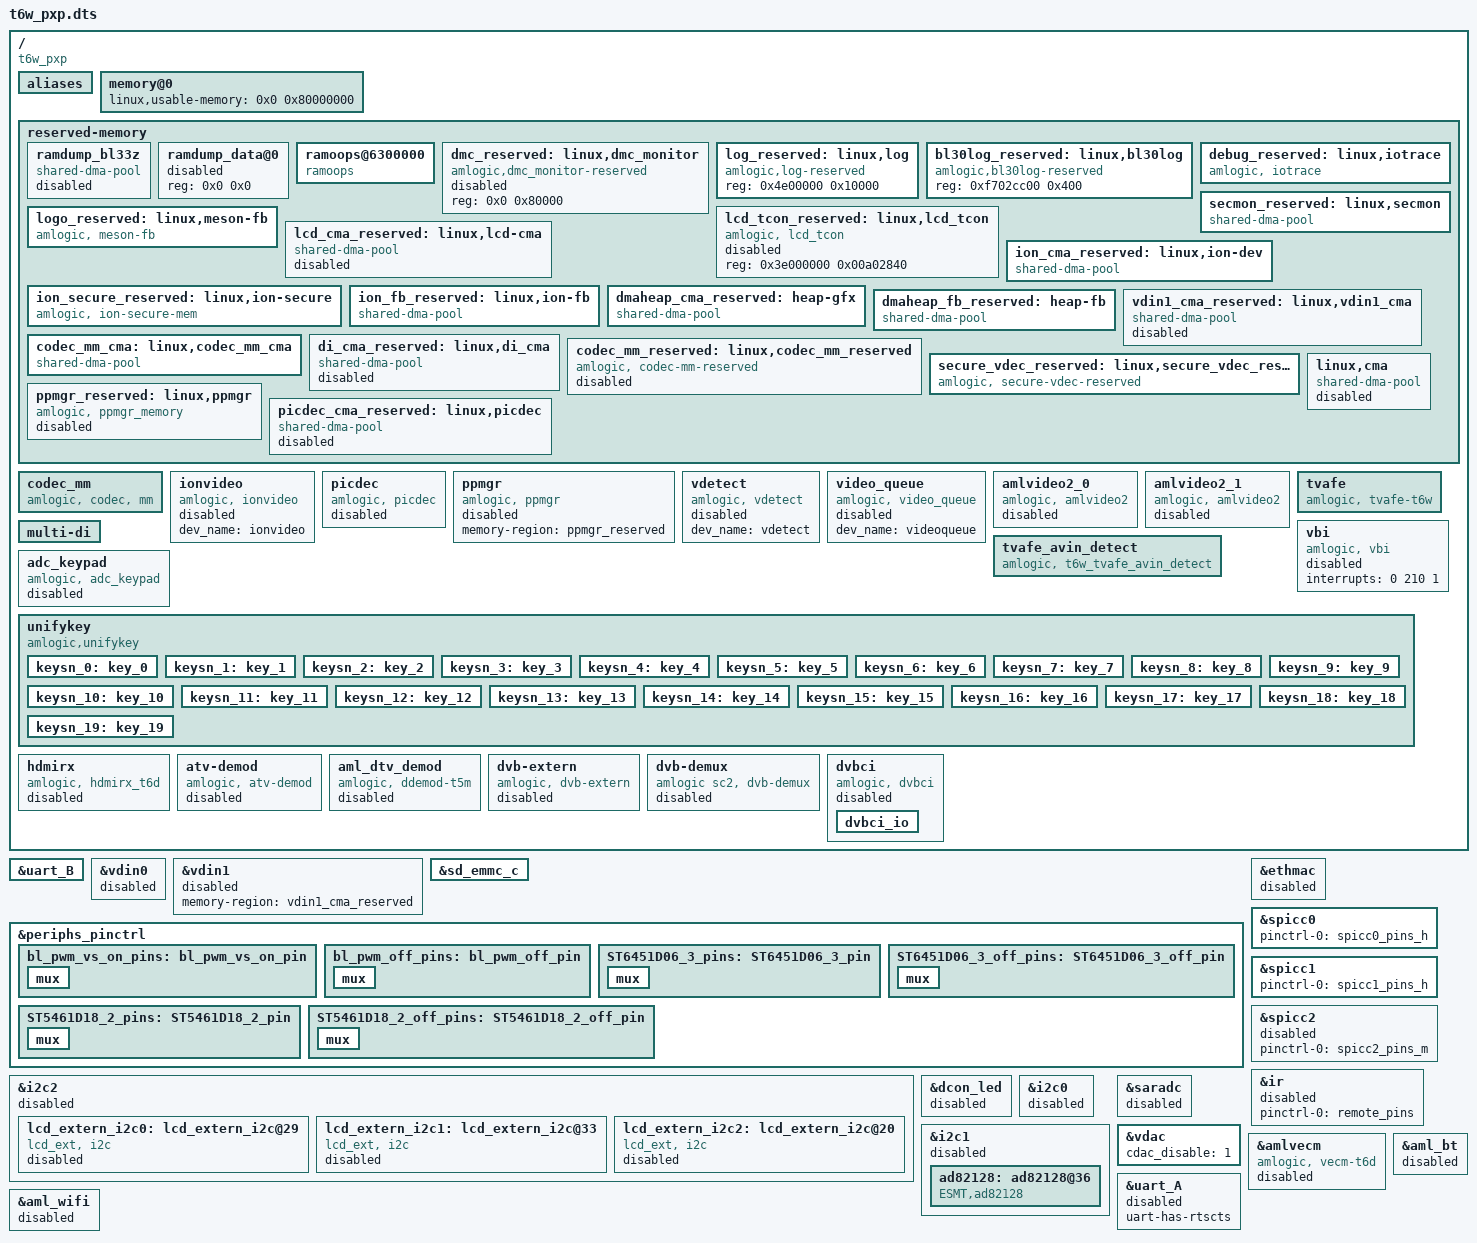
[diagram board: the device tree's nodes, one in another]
// SPDX-License-Identifier: (GPL-2.0+ OR MIT)
/*
 * Copyright (c) 2019 Amlogic, Inc. All rights reserved.
 */

/dts-v1/;

#include "mesont6w.dtsi"
#include "hdr10plus.dtsi"
//#include "mesont6d_drm.dtsi"
#include "firmware_ab.dtsi"
#include "mesont6w_pxp-panel.dtsi"
//#include "mesont6d_audio.dtsi"
/ {
	amlogic-dt-id = "t6w_pxp";
	compatible = "t6w_pxp";
	interrupt-parent = <&gic>;
	#address-cells = <1>;
	#size-cells = <1>;

	aliases {
		serial0 = &uart_B;
		serial1 = &uart_A;
		serial2 = &uart_C;
		tsensor0 = &cpu_tsensor;
		tsensor1 = &top_tsensor;
		spi0 = &spi_nfc;
		spi1 = &spicc0;
		spi2 = &spicc1;
		spi3 = &spicc2;
		spi4 = &spicc3;
		i2c0 = &i2c0;
		i2c1 = &i2c1;
		i2c2 = &i2c2;
		i2c3 = &i2c3;
	};

	memory@0 {
		device_type = "memory";
		linux,usable-memory = <0x0 0x80000000>;
	};

	reserved-memory {
		#address-cells = <1>;
		#size-cells = <1>;
		ranges;

		/* global autoconfigured region for contiguous allocations */
		ramdump_bl33z {
			compatible = "shared-dma-pool";
			size = <0x01800000>;
			alignment = <0x00400000>;
			alloc-ranges = <0x05000000 0x07000000>;
			linux,contiguous-region;
			no-map;
			status = "disabled";
		};

		ramdump_data@0 {
			reg = <0x0 0x0>;
			status = "disabled"; /* disabled as default */
		};

		ramoops@6300000 {
			compatible = "ramoops";
			reg = <0x06300000 0x00080000>;/* addr set in uboot */
			record-size = <0x30000>;
			console-size = <0x40000>;
			ftrace-size = <0x0>;
			pmsg-size = <0x10000>;
		};

		dmc_reserved:linux,dmc_monitor {
			compatible = "amlogic,dmc_monitor-reserved";
			reg = <0x0 0x80000>;
			status = "disabled";
		};

		log_reserved:linux,log {
			compatible = "amlogic,log-reserved";
			reg = <0x4e00000 0x10000>;
		};

		bl30log_reserved:linux,bl30log {
			compatible = "amlogic,bl30log-reserved";
			reg = <0xf702cc00 0x400>;
		};

		debug_reserved:linux,iotrace {
			compatible = "amlogic, iotrace";
			reg = <0x04f00000 0x00100000>;
			io-size = <0x19800>;
			sched-size = <0x2000>;
			irq-size = <0x1000>;
			smc-size = <0x1000>;
			misc-size = <0x1000>;
			iotm-size = <0x3a980>; //240k; v1:20000; v2:15000
		};

		secmon_reserved:linux,secmon {
			compatible = "shared-dma-pool";
			no-map;
			alignment = <0x00100000>;
			reg = <0x05000000 0x01300000>;
		};

		logo_reserved:linux,meson-fb {
			compatible = "amlogic, meson-fb";
			size = <0x800000>;
			alignment = <0x400000>;
			reg = <0x3f800000 0x800000>;
		};

		lcd_tcon_reserved:linux,lcd_tcon {
			compatible = "amlogic, lcd_tcon";
			reg = <0x3e000000 0x00a02840>;
			status = "disabled";
			//no-map;
		};

		lcd_cma_reserved:linux,lcd-cma {
			compatible = "shared-dma-pool";
			reusable;
			/* 512k for lcd dma data */
			size = <0x00080000>;
			reg = <0x3ea80000 0x00080000>;
			status = "disabled";
		};

		ion_cma_reserved:linux,ion-dev {
			compatible = "shared-dma-pool";
			reusable;
			size = <0x0>;
			alignment = <0x400000>;
		};
		/* secure ion for gpu, advice size is 80M */
		ion_secure_reserved:linux,ion-secure {
			compatible = "amlogic, ion-secure-mem";
			no-map;
			size = <0x0>;
			alignment = <0x400000>;
		};
		ion_fb_reserved:linux,ion-fb {
			compatible = "shared-dma-pool";
			reusable;
			size = <0x0>;
			alignment = <0x400000>;
		};
		dmaheap_cma_reserved:heap-gfx {
			compatible = "shared-dma-pool";
			reusable;
			/* 1080p TV android16 size 88M */
			size = <0x5800000>;
			alignment = <0x400000>;
			alloc-ranges = <0x00000000 0x1d400000>;
		};
		dmaheap_fb_reserved:heap-fb {
			compatible = "shared-dma-pool";
			reusable;
			/* 1080p TV android16 size 28M */
			size = <0x1c00000>;
			alignment = <0x400000>;
			alloc-ranges = <0x00000000 0x1d400000>;
		};

		/*  vdin0 CMA pool */
		/*vdin0_cma_reserved:linux,vdin0_cma {*/
		/*	compatible = "shared-dma-pool";*/
		/*	reusable;*/
			/* up to 1920x1080 yuv422 8bit and 5 buffers
			 * 1920x1080x2x5 = 20 M
			 */
		/*	size = <0x0 0x01400000>;*/
		/*	alignment = <0x0 0x400000>;*/
		/*};*/
		/*  vdin1 CMA pool */
		vdin1_cma_reserved:linux,vdin1_cma {
			compatible = "shared-dma-pool";
			reusable;
			/* up to 1920x1080 yuv422 8bit and 5 buffers
			 * 1920x1080x2x5 = 20 M
			 */
			size = <0x01400000>;
			alignment = <0x400000>;
			alloc-ranges = <0x00000000 0x1d400000>;
			status = "disabled";
		};

		codec_mm_cma:linux,codec_mm_cma {
			compatible = "shared-dma-pool";
			reusable;
			/* ion_codec_mm max can alloc size 80M*/
			size = <0xD000000>;
			alignment = <0x400000>;
			alloc-ranges = <0x30000000 0x10000000>;
			linux,contiguous-region;
		};

		/*di CMA pool */
		di_cma_reserved:linux,di_cma {
			compatible = "shared-dma-pool";
			reusable;
			/* buffer_size = 3621952(yuv422 8bit)
			 *  | 4736064(yuv422 10bit)
			 *  | 4074560(yuv422 10bit full pack mode)
			 * 10x3621952=34.6M(0x23) support 8bit
			 * 10x4736064=45.2M(0x2e) support 12bit
			 * 10x4074560=40M(0x28) support 10bit
			 */
			size = <0x000000>;
			//size = <0x0 0x0>;
			alignment = <0x400000>;
			alloc-ranges = <0x0 0x1d400000>;
			status = "disabled";
		};
		/* codec shared reserved */
		codec_mm_reserved:linux,codec_mm_reserved {
			compatible = "amlogic, codec-mm-reserved";
			size = <0x100000>;
			alignment = <0x100000>;
			//no-map;
			status = "disabled";
		};

		secure_vdec_reserved:linux,secure_vdec_reserved {
			compatible = "amlogic, secure-vdec-reserved";
			no-map;
			size = <0x400000>;
			alignment = <0x100000>;
		};

		/* POST PROCESS MANAGER */
		ppmgr_reserved:linux,ppmgr {
			compatible = "amlogic, ppmgr_memory";
			size = <0x100000>;
			alignment = <0x100000>;
			linux,contiguous-region;
			status = "disabled";
		};

		picdec_cma_reserved:linux,picdec {
			compatible = "shared-dma-pool";
			reusable;
			size = <0x100000>;
			alignment = <0x100000>;
			linux,contiguous-region;
			status = "disabled";
		};

		/* global autoconfigured region for contiguous allocations */
		linux,cma {
			compatible = "shared-dma-pool";
			reusable;
			size = <0x800000>;
			alignment = <0x400000>;
			alloc-ranges = <0x0 0x1d400000>;
			linux,cma-default;
			status = "disabled";
		};
	};

	codec_mm {
		compatible = "amlogic, codec, mm";
		memory-region = <&codec_mm_cma &codec_mm_reserved &secure_vdec_reserved>;
		dev_name = "codec_mm";
		status = "okay";
		/* secure memory controller para <switch  align_2n> */
		secure_ctrl_para = <1 16>;
	};

	ionvideo {
		compatible = "amlogic, ionvideo";
		dev_name = "ionvideo";
		status = "disabled";
	};

	picdec {
		compatible = "amlogic, picdec";
		memory-region = <&picdec_cma_reserved>;
		dev_name = "picdec";
		status = "disabled";
	};
	ppmgr {
		compatible = "amlogic, ppmgr";
		memory-region = <&ppmgr_reserved>;
		status = "disabled";
	};
	vdetect {
		compatible = "amlogic, vdetect";
		dev_name = "vdetect";
		status = "disabled";
	};

	video_queue {
		compatible = "amlogic, video_queue";
		dev_name = "videoqueue";
		status = "disabled";
	};
	amlvideo2_0 {
		compatible = "amlogic, amlvideo2";
		dev_name = "amlvideo2";
		status = "disabled";
		amlvideo2_id = <0>;
		cma_mode = <1>;
	};

	amlvideo2_1 {
		compatible = "amlogic, amlvideo2";
		dev_name = "amlvideo2";
		status = "disabled";
		amlvideo2_id = <1>;
		cma_mode = <1>;
	};

	tvafe_avin_detect {
		compatible = "amlogic, t6w_tvafe_avin_detect";
		status = "okay";
		device_mask = <1>;/*bit0:ch1;bit1:ch2*/
		reg = <0xfe00a000 0x400>; /* cvbs irq base */
		interrupts = <0 173 1>;
	};

	tvafe {
		compatible = "amlogic, tvafe-t6w";
		/*memory-region = <&tvafe_cma_reserved>;*/
		status = "okay";
		flag_cma = <1>;/*1:share with codec_mm;0:cma alone*/
		cma_size = <5>;/*MByte*/
		reg = <0xfe072000 0x2000/*tvafe reg base*/
			0xfe008000 0x2000>; /*ana reg base*/
		reserve-iomap = "true";
		tvafe_id = <0>;
		//pinctrl-names = "default";
		/*!!particular sequence, no more and no less!!!*/
		tvafe_pin_mux = <
				3 /* TVAFE_CVBS_IN2, CVBS_IN0 = 0 */
				1 /* TVAFE_CVBS_IN0, CVBS_IN1 */
				2 /* TVAFE_CVBS_IN1, CVBS_IN2 */
				4 /* TVAFE_CVBS_IN3, CVBS_IN3 */
		>;
		clocks = <&clkc CLKID_CDAC_CLK>;
		clock-names = "vdac_clk_gate";
		cutwindow_val_h = <0 0 0 0 8>; /* level 0~4 */
		cutwindow_val_v = <4 8 14 16 24>;  /* level 0~4 */
		horizontal_dir0 = <148 148 148 148 148>;
		horizontal_dir1 = <148 168 166 160 148>;
		horizontal_stp0 = <0 0 0 0 0>;
		horizontal_stp1 = <0 0 0 0 0>;
		macrovision = <1>;
	};

	vbi {
		compatible = "amlogic, vbi";
		status = "disabled";
		interrupts = <0 210 1>;
	};

	multi-di {
		//status = "disabled";
		/***************************************************
		 * memory: default is 4
		 *	0:use reserved;
		 *	1:use cma;
		 *	2:use cma as reserved
		 *  4:use codec mem
		 ***************************************************/
		flag_cma = <4>;//
		//memory-region = <&di_cma_reserved>;
		/***************************************************
		 * clock-range: <min max>
		 *	default: <334 667>
		 ***************************************************/
		//clock-range = <334 667>;
		/***************************************************
		 * en_4k: t5w support 4k
		 ***************************************************/
		//en_4k = <1>;
		//keep_dec_vf = <2>;
		//po_fmt = <6>;
		/***************************************************
		 * post_nub: default is 11 (T7/T3/SC2/S4 new path)
		 * local 7*4075520 = 28
		 * post 11*5222400 = 56 //??
		 ***************************************************/
		post_nub = <11>;
		/***************************************************
		 * 0:not support
		 * bit 0: for 4k
		 * bit 1: for 1080p
		 ***************************************************/
		//alloc_sct = <1>;
		/***************************************************
		 * hf: default is 0 (T7/T3/SC2/S4 new path)
		 * 0:not enable;
		 * 1: enable
		 ***************************************************/
		hf = <0>;
		//afbce_loss_en = <1>;
		/***************************************************
		 * loss mode for di out (T5w)
		 * 0:not set loss mode for di out;
		 * 1:1:check the loss flag in vf and set for di
		 ***************************************************/
	};/* end of multi-di */

	/* for external keypad */
	adc_keypad {
		compatible = "amlogic, adc_keypad";
		status = "disabled";
		key_name = "power","vol-","vol+","enter","menu","source","exit";
		key_num = <7>;
		io-channels = <&saradc SARADC_CH1>,<&saradc SARADC_CH2>;
		io-channel-names = "key-chan-1", "key-chan-2";
		key_chan = <SARADC_CH1 SARADC_CH1 SARADC_CH1 SARADC_CH1
			SARADC_CH1 SARADC_CH2 SARADC_CH2>;
		key_code = <116 114 115 28 139 466 174>;
		key_val = <0 252 468 684 892 252 468>; // Unit: millivolt
		key_tolerance = <70 70 70 70 70 70 70>; // Unit: millivolt
		mboxes = <&mbox_fifo T6W_REE2AO_KEYPAD>;
	};

	unifykey {
		compatible = "amlogic,unifykey";

		unifykey-num = <20>;
		unifykey-index-0 = <&keysn_0>;
		unifykey-index-1 = <&keysn_1>;
		unifykey-index-2 = <&keysn_2>;
		unifykey-index-3 = <&keysn_3>;
		unifykey-index-4 = <&keysn_4>;
		unifykey-index-5 = <&keysn_5>;
		unifykey-index-6 = <&keysn_6>;
		unifykey-index-7 = <&keysn_7>;
		unifykey-index-8 = <&keysn_8>;
		unifykey-index-9 = <&keysn_9>;
		unifykey-index-10= <&keysn_10>;
		unifykey-index-11 = <&keysn_11>;
		unifykey-index-12 = <&keysn_12>;
		unifykey-index-13 = <&keysn_13>;
		unifykey-index-14 = <&keysn_14>;
		unifykey-index-15 = <&keysn_15>;
		unifykey-index-16 = <&keysn_16>;
		unifykey-index-17 = <&keysn_17>;
		unifykey-index-18 = <&keysn_18>;
		unifykey-index-19 = <&keysn_19>;

		keysn_0: key_0{
			key-name = "usid";
			key-device = "normal";
			key-permit = "read","write","del";
		};
		keysn_1:key_1{
			key-name = "mac";
			key-device  = "normal";
			key-permit = "read","write","del";
		};
		keysn_2:key_2{
			key-name = "hdcp";
			key-device = "secure";
			key-type  = "sha1";
			key-permit = "read","write","del";
		};
		keysn_3:key_3{
			key-name = "secure_boot_set";
			key-device = "efuse";
			key-permit = "write";
		};
		keysn_4:key_4{
			key-name = "mac_bt";
			key-device = "normal";
			key-permit = "read","write","del";
			key-type  = "mac";
		};
		keysn_5:key_5{
			key-name = "mac_wifi";
			key-device = "normal";
			key-permit = "read","write","del";
			key-type  = "mac";
		};
		keysn_6:key_6{
			key-name = "hdcp2_tx";
			key-device = "normal";
			key-permit = "read","write","del";
		};
		keysn_7:key_7{
			key-name = "hdcp2_rx";
			key-device = "normal";
			key-permit = "read","write","del";
		};
		keysn_8:key_8{
			key-name = "widevinekeybox";
			key-device = "secure";
			key-type = "sha1";
			key-permit = "read","write","del";
		};
		keysn_9:key_9{
			key-name = "deviceid";
			key-device = "normal";
			key-permit = "read","write","del";
		};
		keysn_10:key_10{
			key-name = "hdcp22_fw_private";
			key-device = "secure";
			key-permit = "read","write","del";
		};
		keysn_11:key_11{
			key-name = "hdcp22_rx_private";
			key-device = "secure";
			key-permit = "read","write","del";
		};
		keysn_12:key_12{
			key-name = "hdcp22_rx_fw";
			key-device = "normal";
			key-permit = "read","write","del";
		};
		keysn_13:key_13{
			key-name = "hdcp14_rx";
			key-device = "normal";
			key-type  = "sha1";
			key-permit = "read","write","del";
		};
		keysn_14:key_14{
			key-name = "prpubkeybox";// PlayReady
			key-device = "secure";
			key-permit = "read","write","del";
		};
		keysn_15:key_15{
			key-name = "prprivkeybox";// PlayReady
			key-device = "secure";
			key-permit = "read","write","del";
		};
		keysn_16:key_16{
			key-name = "attestationkeybox";// attestation key
			key-device = "secure";
			key-permit = "read","write","del";
		};
		keysn_17:key_17{
			key-name = "lcd_tcon_spi";
			key-device = "normal";
			key-permit = "read","write","del";
		};
		keysn_18:key_18{
			key-name = "attestationdevidbox";// attest dev id box
			key-device = "secure";
			key-permit = "read","write","del";
		};
		keysn_19:key_19{
			key-name = "oemkey";
			key-device = "normal";
			key-permit = "read","write","del";
		};
	}; /* End unifykey */

	hdmirx {
		compatible = "amlogic, hdmirx_t6d";
		#address-cells=<1>;
		#size-cells=<1>;
		/*memory-region = <&hdmirx_emp_cma_reserved>;*/
		status = "disabled";
		pinctrl-names = "hdmirx_pins";
		pinctrl-0 = <&hdmirx_a_mux &hdmirx_b_mux
			&hdmirx_c_mux>;
		repeat = <0>;
		/*power-domains = <&pwrdm PDIP_T6D_VPU_HDMI>;*/
		interrupts = <0 57 IRQ_TYPE_LEVEL_HIGH>;
		clocks =<&clkc CLKID_HDMIRX_CFG>,
			<&clkc CLKID_HDMIRX_ACR>,
			<&clkc CLKID_HDMIRX_METER>,
			<&clkc CLKID_HDMIRX_2M>,
			<&clkc CLKID_HDMIRX_5M>,
			<&clkc CLKID_HDMIRX_HDCP>,
			<&xtal>,
			<&clkc CLKID_FCLK_DIV4>,
			<&clkc CLKID_FCLK_DIV5>;
		clock-names = "hdmirx_cfg_clk",
				"cts_hdmirx_acr_ref_clk",
				"cts_hdmirx_meter_clk",
				"cts_hdmirx_2m_clk",
				"cts_hdmirx_5m_clk",
				"cts_hdmirx_hdcp2x_eclk",
				"xtal",
				"fclk_div4",
				"fclk_div5";
		//power-domains = <&pwrdm 2>;
		hdmirx_id = <0>;
		en_4k_2_2k = <0>;
		hpd_low_cec_off = <1>;
		arc_port = <0>;
		/* for 2.2R:0x8, for 5.1R:0x6 */
		term_lvl = <0x6>;
		vrr_range_dynamic_update_en = <1>;
		/* bit4: enable feature, bit3~0: port number */
		disable_port = <0x0>;
		/* MAP_ADDR_MODULE_CBUS */
		/* MAP_ADDR_MODULE_HIU */
		/* MAP_ADDR_MODULE_HDMIRX_CAPB3 */
		/* MAP_ADDR_MODULE_SEC_AHB */
		/* MAP_ADDR_MODULE_SEC_AHB2 */
		/* MAP_ADDR_MODULE_APB4 */
		/* MAP_ADDR_MODULE_TOP */
		/* MAP_ADDR_MODULE_CLK_CTRL */
		/* MAP_ADDR_MODULE_ANA_CTRL */
		reg = < 0x0 0x0
			0x0 0x0
			0x0 0x0
			0x0 0x0
			0x0 0x0
			0x0 0x0
			0xfe398000 0x18000
			0xfe000000 0x2ffff
			0xfe008000 0x334>;
	};

	/* Audio Related start */
//	auge_sound {
//		compatible = "amlogic, auge-sound-card";
//		status = "disabled";
//		aml-audio-card,name = "AML-AUGESOUND";
//
//		// avout_mute-gpios = <&gpio GPIOH_27 GPIO_ACTIVE_HIGH>;
//
//		/* headphone insert det */
//		// hp-det-gpios = <&analog_gpio CDAC_IOUT GPIO_ACTIVE_LOW>;
//
//		interrupts = <GIC_SPI 51 IRQ_TYPE_EDGE_RISING>;
//		interrupt-names = "audio_exception64";
//
//		aml-audio-card,dai-link@0 {
//			format = "i2s";
//			mclk-fs = <256>;
//			//continuous-clock;
//			//bitclock-inversion;
//			//frame-inversion;
//			/* master mode */
//			bitclock-master = <&tdma>;
//			frame-master = <&tdma>;
//			/* slave mode */
//			/* bitclock-master = <&tdmacodec>; */
//			/* frame-master = <&tdmacodec>; */
//			/* suffix-name, sync with android audio hal used for */
//			suffix-name = "alsaPORT-pcm";
//			tdmacpu: cpu {
//				sound-dai = <&tdma>;
//				dai-tdm-slot-tx-mask =
//							<1 1>;
//				dai-tdm-slot-rx-mask =
//							<1 1>;
//				dai-tdm-slot-num = <2>;
//				dai-tdm-slot-width = <32>;
//				system-clock-frequency = <12288000>;
//			};
//			tdmacodec: codec {
//				sound-dai = <&dummy_codec>;
//			};
//		};
//
//		aml-audio-card,dai-link@1 {
//			format = "i2s";
//			mclk-fs = <256>;
//			continuous-clock;
//			//bitclock-inversion;
//			//frame-inversion;
//			/* master mode */
//			bitclock-master = <&tdmb>;
//			frame-master = <&tdmb>;
//			/* slave mode */
//			//bitclock-master = <&tdmbcodec>;
//			//frame-master = <&tdmbcodec>;
//			/* suffix-name, sync with android audio hal used for */
//			suffix-name = "alsaPORT-i2s-i2s4hdmirx";
//			cpu {
//				sound-dai = <&tdmb>;
//				dai-tdm-slot-tx-mask = <1 1>;
//				dai-tdm-slot-rx-mask = <1 1>;
//				dai-tdm-slot-num = <2>;
//				dai-tdm-slot-width = <32>;
//				system-clock-frequency = <12288000>;
//			};
//			tdmbcodec: codec {
//				prefix-names = "AMP";
//				sound-dai = <&ad82128 &acodec>;
//			};
//		};
//
//		aml-audio-card,dai-link@2 {
//			format = "i2s";
//			mclk-fs = <256>;
//			//continuous-clock;
//			//bitclock-inversion;
//			//frame-inversion;
//			/* master mode */
//			bitclock-master = <&tdmc>;
//			frame-master = <&tdmc>;
//			/* slave mode */
//			//bitclock-master = <&tdmccodec>;
//			//frame-master = <&tdmccodec>;
//			/* suffix-name, sync with android audio hal used for */
//			suffix-name = "alsaPORT-i2s4parser";
//			cpu {
//				sound-dai = <&tdmc>;
//				dai-tdm-slot-tx-mask = <1 1>;
//				dai-tdm-slot-rx-mask = <1 1>;
//				dai-tdm-slot-num = <2>;
//				dai-tdm-slot-width = <32>;
//				system-clock-frequency = <12288000>;
//			};
//			tdmccodec: codec {
//				sound-dai = <&dummy_codec>;
//			};
//		};
//
//		aml-audio-card,dai-link@3 {
//			mclk-fs = <64>;
//			/* suffix-name, sync with android audio hal used for */
//			suffix-name = "alsaPORT-pdm-builtinmic";
//			cpu {
//				sound-dai = <&pdma>;
//			};
//			codec {
//				sound-dai = <&dummy_codec>;
//			};
//		};
//
//		aml-audio-card,dai-link@4 {
//			mclk-fs = <128>;
//			continuous-clock;
//			/* suffix-name, sync with android audio hal used for */
//			suffix-name = "alsaPORT-spdif";
//			cpu {
//				sound-dai = <&spdifa>;
//				system-clock-frequency = <6144000>;
//			};
//			codec {
//				sound-dai = <&dummy_codec>;
//			};
//		};
//
//		aml-audio-card,dai-link@5 {
//			mclk-fs = <128>;
//			continuous-clock;
//			suffix-name = "alsaPORT-spdifb";
//			cpu {
//				sound-dai = <&spdifb>;
//				system-clock-frequency = <6144000>;
//			};
//			codec {
//				sound-dai = <&dummy_codec>;
//			};
//		};
//
//		aml-audio-card,dai-link@6 {
//			mclk-fs = <256>;
//			suffix-name = "alsaPORT-tv";
//			cpu {
//				sound-dai = <&extn>;
//				system-clock-frequency = <12288000>;
//			};
//			codec {
//				sound-dai = <&dummy_codec>;
//			};
//		};
//
//		aml-audio-card,dai-link@7 {
//			mclk-fs = <256>;
//			continuous-clock;
//			suffix-name = "alsaPORT-loopback";
//			cpu {
//				sound-dai = <&loopbacka>;
//				system-clock-frequency = <12288000>;
//			};
//			codec {
//				sound-dai = <&dummy_codec>;
//			};
//		};
//	};
	/* Audio Related end */

	atv-demod {
		compatible = "amlogic, atv-demod";
		status = "disabled";
		btsc_sap_mode = <1>;
		interrupts = <0 94 1>;
		pinctrl-names="atvdemod_agc_pins";
		pinctrl-0=<&atvdemod_agc_pins>;
		reg = <0xfe0be000 0x2000    // demod reg
				0xfe000000 0x2000   // hiu reg
				0x0 0x0             // periphs reg
				0xfe0bc000 0x2000>; // adec reg
		common_agc = <1>;
	};

	aml_dtv_demod {
		compatible = "amlogic, ddemod-t5m";
		dev_name = "aml_dtv_demod";
		status = "disabled";
		diseqc_name = "sgm_41286";
		pinctrl-names="if_agc_pins", "diseqc_out", "rf_agc_pins";
		pinctrl-0=<&dtvdemod_if_agc_pins>;
		pinctrl-1=<&diseqc_out>;
		pinctrl-2=<&dtvdemod_rf_agc_pins>;
		//pinctrl-3=<&diseqc_in>;
		lnb_en-gpios = <&gpio GPIOZ_2 GPIO_ACTIVE_HIGH>;
		lnb_sel-gpios = <&gpio GPIOZ_3 GPIO_ACTIVE_HIGH>;
		interrupts = <GIC_SPI 87 IRQ_TYPE_EDGE_RISING>;
		interrupt-names = "demod_isr";
		//power-domains = <&pwrdm PDID_T5M_DEMOD>;
		clocks = <&clkc CLKID_DEMOD_32K>;
		clock-names = "demod_32k";
		reg = <0xfe360000 0x10000	//dtv demod base
			   0xfe000000 0x2000	//hiu reg base
			   0xff800000 0x1000	//io_aobus_base
			   0xfe002000 0x2000>;	//reset

		spectrum = <1>;
		cma_mem_size = <16>; // MB
	};

	dvb-extern {
		compatible = "amlogic, dvb-extern";
		dev_name = "dvb-extern";
		status = "disabled";

		fe_num = <1>;
		fe0_demod = "internal";

		tuner_num = <2>; // tuner number, multi tuner support
		tuner0_name = "r842_tuner";
		tuner0_i2c_adap = <&i2c0>;
		tuner0_i2c_addr = <0xF6>; // 8 bits
		tuner0_xtal = <1>;       // 0: 16MHz, 1: 24MHz
		tuner0_xtal_mode = <0>;  // NO_SHARE_XTAL(0), SLAVE_XTAL_SHARE(3)
		tuner0_xtal_cap = <38>;

		tuner1_name = "rt710_tuner";
		tuner1_i2c_adap = <&i2c0>;
		tuner1_i2c_addr = <0xF4>; // 8 bits
		tuner1_xtal = <0>;       // 0: 16MHz, 1: 24MHz
		tuner1_xtal_mode = <0>;  // NO_SHARE_XTAL(0), SLAVE_XTAL_SHARE(3)
		tuner1_xtal_cap = <30>;
	};

	dvb-demux {
		compatible = "amlogic sc2, dvb-demux"; /* same as sc2 */
		dev_name = "dvb-demux";
		status = "disabled";

		reg = <0xfe000000 0x480000>;

		dmxdev_num = <0x6>;

		tsn_from = "demod";

		/*single demod setting */
		ts1_sid = <0x21>;
		ts1 = "parallel";
		ts1_control = <0x0>;
		ts1_invert = <0>;

		ts2_sid = <0x22>;
		ts2 = "parallel";
		ts2_control = <0x0>;
		ts2_invert = <0>;
		pinctrl-names = "p_ts1";
		pinctrl-0 = <&dvb_p_ts1_pins>;
	};

	dvbci {
		compatible = "amlogic, dvbci";
		dev_name = "dvbci";
		status = "disabled";

		io_type = <4>; /* 0=iobus,1=spi,2=cimax,3=spi-t312 4:T5D,ci bus*/
		addr_ts_mode_multiplex = <0>; /*AY301 not multi ts and addr,default 1*/
		le_enable_level = <0>; /*LE pin enable level*/
		/*gpio pin define*/
		pinctrl-names= "ci_ts_pins", "ci_addr_pins";
		pinctrl-0=<&dvb_ci_bus_pins_all &ci_ts_pins &ci_ts_clk_pins>;
		pinctrl-1=<&dvb_ci_bus_pins &ci_addr_pins &ci_gpio_pins>;
		reg = <0xFE080000 0x1FFF>;
		/*irq define, t5m not use these irq*/
		//interrupts = <0 186 1
		//		0 187 1>;
		//interrupt-names = "irq_cmp",
		//			"irq_timeout";
		dvbci_io {
			/*gpio define  GPIOM_27 GPIOM_28 GPIOM_30*/
			cd_pin1 = <&gpio       GPIOM_27       GPIO_ACTIVE_HIGH>;
			pwr_pin = <&gpio       GPIOM_28       GPIO_ACTIVE_HIGH>;
			le_pin = <&gpio       GPIOM_29       GPIO_ACTIVE_HIGH>;
		};
	};
}; /* end of / */

//&drm_vpu {
//	status = "disabled";
//	logo_addr = "0x3f800000";
//
//	connectors_dev: port@1 {
//		drm_to_lcd0: endpoint@1 {
//			reg = <1>;
//			remote-endpoint = <&lcd0_to_drm>;
//		};
//	};
//};
//
//&lcd {
//	status = "disabled";
//	ports {
//		port {
//			#address-cells = <1>;
//			#size-cells = <0>;
//			lcd0_to_drm: endpoint@0 {
//				reg = <0>;
//				remote-endpoint = <&drm_to_lcd0>;
//			};
//		};
//	};
//};

&uart_B {
	status = "okay";
};

/*if you want to use vdin just modify status to "ok"*/
&vdin0 {
	/*memory-region = <&vdin0_cma_reserved>;*/
	status = "disabled";
	/*MByte, if 10bit disable: 64M(YUV422),
	 *if 10bit enable: 64*1.5 = 96M(YUV422)
	 *if support 4K2K-YUV444-10bit-WR:3840*2160*4*4 ~= 128M
	 *if support 4K2K-YUV422-10bit-wr:3840*2160*3*4 ~= 96M
	 *if support 4K2K-YUV422-8BIT-WR:3840*2160*2*4 ~= 64M
	 *if support 1080p-YUV422-8BIT-WR:1920*1080*2*4 ~= 16M
	 * onebuffer:
	 * worst case:(4096*2160*3 + 2M(afbce issue)) = 27.5M
	 * dw:960x540x3 = 1.5M
	 * total size:(27.5+1.5)x buffernumber
	 */
	cma_size = <330>;
	frame_buff_num = <10>;
};

&vdin1 {
	memory-region = <&vdin1_cma_reserved>;
	status = "disabled";
};

&sd_emmc_c {
	status = "okay";
	pinctrl-0 = <&emmc_pins>, <&emmc_ds_pins>;
	pinctrl-1 = <&emmc_clk_gate_pins>;
	pinctrl-names = "default", "clk-gate";

	bus-width = <8>;
	cap-mmc-highspeed;
	//mmc-ddr-1_8v;
	//mmc-hs200-1_8v;
	//mmc-hs400-1_8v;
	max-frequency = <200000000>;
	non-removable;
	disable-wp;
//	amlogic,dram-access-quirk;

//	mmc-pwrseq = <&emmc_pwrseq>;
//	vmmc-supply = <&vddao_3v3>;
//	vqmmc-supply = <&vddao_1v8>;
};

&periphs_pinctrl {
	/*backlight*/
	bl_pwm_vs_on_pins:bl_pwm_vs_on_pin {
		mux {
			groups = "pwm_vs_h12";
			function = "pwm_vs";
		};
	};
	bl_pwm_off_pins:bl_pwm_off_pin {
		mux {
			groups = "GPIOH_12";
			function = "gpio_periphs";
			output-low;
		};
	};
	ST6451D06_3_pins: ST6451D06_3_pin {
		mux {
			groups = "tcon_1","tcon_2","tcon_3",
				"tcon_4","tcon_5","tcon_6",
				"tcon_8","tcon_lock";
			function = "tcon";
		};
	};
	ST6451D06_3_off_pins: ST6451D06_3_off_pin {
		mux {
			groups = "GPIOH_1","GPIOH_2","GPIOH_3",
				"GPIOH_4","GPIOH_5","GPIOH_6",
				"GPIOH_8", "GPIOH_0";
				function = "gpio_periphs";
			input-enable;
		};
	};
	ST5461D18_2_pins: ST5461D18_2_pin {
		mux {
			groups = "tcon_1","tcon_2","tcon_3",
				"tcon_4","tcon_5","tcon_6",
				"tcon_8","tcon_lock";
			function = "tcon";
		};
	};
	ST5461D18_2_off_pins: ST5461D18_2_off_pin {
		mux {
			groups = "GPIOH_1","GPIOH_2","GPIOH_3",
				"GPIOH_4","GPIOH_5","GPIOH_6",
				"GPIOH_8","GPIOH_0";
				function = "gpio_periphs";
			input-enable;
		};
	};
};

&i2c2 {
	status = "disabled";
	clock-frequency = <100000>;
	pinctrl-names="default";
	pinctrl-0=<&i2c2_pins2>;

	lcd_extern_i2c0: lcd_extern_i2c@29 {
		compatible = "lcd_ext, i2c";
		dev_name = "i2c_HV650LS";
		reg = <0x29>;
		status = "disabled";
	};

	lcd_extern_i2c1: lcd_extern_i2c@33 {
		compatible = "lcd_ext, i2c";
		dev_name = "i2c_CS602";
		reg = <0x33>;
		status = "disabled";
	};

	lcd_extern_i2c2: lcd_extern_i2c@20 {
		compatible = "lcd_ext, i2c";
		dev_name = "i2c_CS901";
		reg = <0x20>;
		status = "disabled";
	};
};

&ethmac {
	status = "disabled";
	phy-handle = <&internal_ephy>;
	phy-mode = "rmii";
};

&spicc0 {	//for TCON
	status = "okay";
	pinctrl-names = "default";
	pinctrl-0 = <&spicc0_pins_h>;
};

&spicc1 {	//for UWB/LocalDimm
	status = "okay";
	pinctrl-names = "spi_pinmux"; //Compatible with BCON
	pinctrl-0 = <&spicc1_pins_h>;
};

&spicc2 {	//for UWB/LocalDimm
	status = "disabled";
	pinctrl-names = "default";
	pinctrl-0 = <&spicc2_pins_m>;
};

&ir {
	status = "disabled";
	pinctrl-names = "default";
	pinctrl-0 = <&remote_pins>;
};

&dcon_led {
	status = "disabled";
	led_number = <13>;
	pinctrl-names = "default";
	pinctrl-0 = <&dcon_led_pins1>;
};

&i2c0 {
	status = "disabled";
	clock-frequency = <300000>;
	pinctrl-names="default";
	pinctrl-0=<&i2c0_pins1>;
};

&i2c1 {
	status = "disabled";
	pinctrl-names = "default";
	pinctrl-0 = <&i2c1_pins1>;
	clock-frequency = <100000>;
	ad82128: ad82128@36 {
		compatible = "ESMT,ad82128";
		#sound-dai-cells = <0>;
		reset_pin = <&gpio GPIOD_9 GPIO_ACTIVE_HIGH>;
		reg = <0x36>;
		status = "okay";
	};
};

&saradc {
	status = "disabled";
};

&vdac {
	cdac_disable = <1>;
};

&amlvecm {
	compatible = "amlogic, vecm-t6d";
	dev_name = "aml_vecm";
	status = "disabled";
	gamma_en = <1>;/*1:enable ;0:disable*/
	wb_en = <1>;/*1:enable ;0:disable*/
	cm_en = <1>;/*1:enable ;0:disable*/
	wb_sel = <0>;/*1:mtx ;0:gainoff*/
	osd_pic_en = <1>;/*1:enable osd picture setting;0:disable*/
	vlock_en = <1>;/*1:enable;0:disable*/
	vlock_mode = <0x8>;
	//vrr_priority = <1>;/*1:game mode vrr always on;0:vrr on depend on vrr signal*/
	/*vlock work mode:
	 *bit0:auto ENC
	 *bit1:auto PLL
	 *bit2:manual PLL
	 *bit3:manual ENC
	 *bit4:manual soft ENC
	 *bit5:manual MIX PLL ENC
	 */
	vlock_pll_m_limit = <1>;
	vlock_line_limit = <2>;
	interrupts = <0 207 1>;
	interrupt-names = "lc_curve";
};

&uart_A {
	status = "disabled";
	uart-has-rtscts;
};

&aml_wifi{
	status = "disabled";
	power_on-gpios = <&gpio   GPIOD_11  GPIO_ACTIVE_HIGH>;
	disable-wifi-32k;
};

&aml_bt {
	status = "disabled";
	bt_en-gpios = <&gpio  GPIOD_11  GPIO_ACTIVE_HIGH>;
	btwakeup-gpios = <&gpio  GPIOD_8  GPIO_ACTIVE_HIGH>;
	hostwake-gpios = <&gpio  GPIOD_12  GPIO_ACTIVE_HIGH>;
	power_down_disable = <1>;
};
